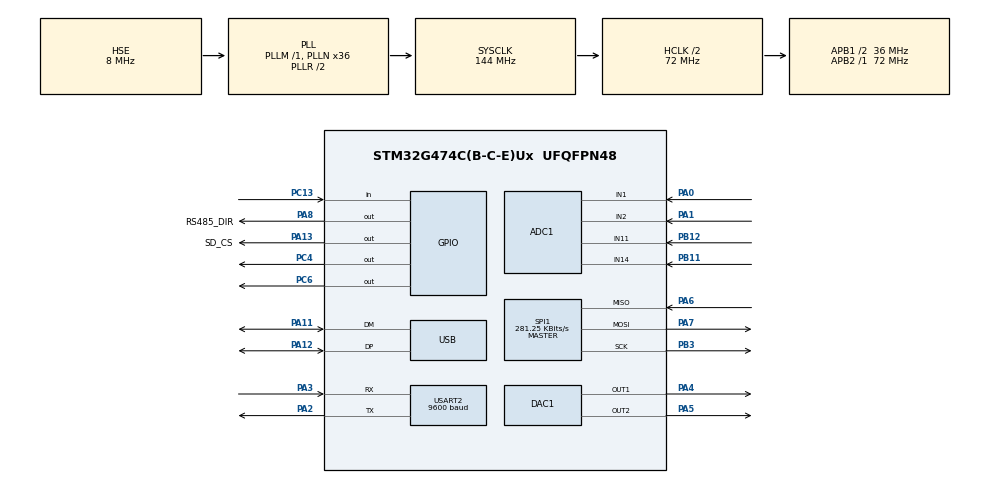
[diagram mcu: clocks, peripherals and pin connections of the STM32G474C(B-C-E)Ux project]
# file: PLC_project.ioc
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ADC1.Channel-0\#ChannelRegularConversion=ADC_CHANNEL_1
ADC1.NbrOfConversionFlag=1
ADC1.OffsetNumber-0\#ChannelRegularConversion=ADC_OFFSET_NONE
ADC1.Rank-0\#ChannelRegularConversion=1
ADC1.SamplingTime-0\#ChannelRegularConversion=ADC_SAMPLETIME_2CYCLES_5
ADC1.master=1
DAC1.DAC_Channel-DAC_OUT2_ExtAndInt=DAC_CHANNEL_2
Dma.Request0=USART2_RX
Dma.Request1=USART2_TX
Dma.USART2_RX.0.Direction=DMA_PERIPH_TO_MEMORY
Dma.USART2_RX.0.EventEnable=DISABLE
Dma.USART2_RX.0.Instance=DMA1_Channel1
Dma.USART2_RX.0.MemDataAlignment=DMA_MDATAALIGN_BYTE
Dma.USART2_RX.0.MemInc=DMA_MINC_ENABLE
Dma.USART2_RX.0.Mode=DMA_NORMAL
Dma.USART2_RX.0.PeriphDataAlignment=DMA_PDATAALIGN_BYTE
Dma.USART2_RX.0.PeriphInc=DMA_PINC_DISABLE
Dma.USART2_RX.0.Polarity=HAL_DMAMUX_REQ_GEN_RISING
Dma.USART2_RX.0.Priority=DMA_PRIORITY_HIGH
Dma.USART2_RX.0.RequestNumber=1
Dma.USART2_RX.0.SignalID=NONE
Dma.USART2_RX.0.SyncEnable=DISABLE
Dma.USART2_RX.0.SyncPolarity=HAL_DMAMUX_SYNC_NO_EVENT
Dma.USART2_RX.0.SyncRequestNumber=1
Dma.USART2_RX.0.SyncSignalID=NONE
Dma.USART2_TX.1.Direction=DMA_MEMORY_TO_PERIPH
Dma.USART2_TX.1.EventEnable=DISABLE
Dma.USART2_TX.1.Instance=DMA1_Channel2
Dma.USART2_TX.1.MemDataAlignment=DMA_MDATAALIGN_BYTE
Dma.USART2_TX.1.MemInc=DMA_MINC_ENABLE
Dma.USART2_TX.1.Mode=DMA_NORMAL
Dma.USART2_TX.1.PeriphDataAlignment=DMA_PDATAALIGN_BYTE
Dma.USART2_TX.1.PeriphInc=DMA_PINC_DISABLE
Dma.USART2_TX.1.Polarity=HAL_DMAMUX_REQ_GEN_RISING
Dma.USART2_TX.1.Priority=DMA_PRIORITY_HIGH
Dma.USART2_TX.1.RequestNumber=1
Dma.USART2_TX.1.SignalID=NONE
Dma.USART2_TX.1.SyncEnable=DISABLE
Dma.USART2_TX.1.SyncPolarity=HAL_DMAMUX_SYNC_NO_EVENT
Dma.USART2_TX.1.SyncRequestNumber=1
Dma.USART2_TX.1.SyncSignalID=NONE
Mcu.Family=STM32G4
Mcu.Name=STM32G474C(B-C-E)Ux
Mcu.Package=UFQFPN48
NVIC.DMA1_Channel1_IRQn=true\:1\:0\:true\:false\:true\:false\:true\:true
NVIC.DMA1_Channel2_IRQn=true\:1\:0\:true\:false\:true\:false\:true\:true
NVIC.PriorityGroup=NVIC_PRIORITYGROUP_4
NVIC.USART2_IRQn=true\:2\:0\:true\:false\:true\:true\:true\:true
NVIC.USB_LP_IRQn=true\:0\:0\:false\:false\:true\:false\:true\:true
PA0.Mode=IN1-Single-Ended
PA0.Signal=ADC1_IN1
PA1.Mode=IN2-Single-Ended
PA1.Signal=ADC1_IN2
PA11.Mode=Device
PA11.Signal=USB_DM
PA12.Mode=Device
PA12.Signal=USB_DP
PA13.GPIO_Label=SD_CS
PA13.Signal=GPIO_Output
PA2.Mode=Asynchronous
PA2.Signal=USART2_TX
PA3.Mode=Asynchronous
PA3.Signal=USART2_RX
PA4.Signal=COMP_DAC11_group
PA5.Signal=COMP_DAC12_group
PA6.Mode=Full_Duplex_Master
PA6.Signal=SPI1_MISO
PA7.Mode=Full_Duplex_Master
PA7.Signal=SPI1_MOSI
PA8.GPIO_Label=RS485_DIR
PA8.Signal=GPIO_Output
PB11.Mode=IN14-Single-Ended
PB11.Signal=ADC1_IN14
PB12.Mode=IN11-Single-Ended
PB12.Signal=ADC1_IN11
PB3.Mode=Full_Duplex_Master
PB3.Signal=SPI1_SCK
PC13.GPIO_PuPd=GPIO_PULLDOWN
PC13.Signal=GPIO_Input
PC4.Signal=GPIO_Output
PC6.Signal=GPIO_Output
PF0-OSC_IN.Mode=HSE-External-Oscillator
PF0-OSC_IN.Signal=RCC_OSC_IN
PF1-OSC_OUT.Mode=HSE-External-Oscillator
PF1-OSC_OUT.Signal=RCC_OSC_OUT
ProjectManager.HeapSize=0x200
ProjectManager.StackSize=0x400
ProjectManager.TargetToolchain=STM32CubeIDE
RCC.ADC12Freq_Value=144000000
RCC.ADC345Freq_Value=144000000
RCC.AHBCLKDivider=RCC_SYSCLK_DIV2
RCC.AHBFreq_Value=72000000
RCC.APB1CLKDivider=RCC_HCLK_DIV2
RCC.APB1Freq_Value=36000000
RCC.APB1TimFreq_Value=72000000
RCC.APB2Freq_Value=72000000
RCC.APB2TimFreq_Value=72000000
RCC.CortexFreq_Value=72000000
RCC.EXTERNAL_CLOCK_VALUE=12288000
RCC.HCLKFreq_Value=72000000
RCC.HSE_VALUE=8000000
RCC.HSI48_VALUE=48000000
RCC.HSI_VALUE=16000000
RCC.LSE_VALUE=32768
RCC.PLLN=36
RCC.PLLQ=RCC_PLLQ_DIV6
RCC.PLLSourceVirtual=RCC_PLLSOURCE_HSE
RCC.SYSCLKFreq_VALUE=144000000
RCC.SYSCLKSource=RCC_SYSCLKSOURCE_PLLCLK
RCC.USBFreq_Value=48000000
RCC.VCOOutputFreq_Value=288000000
SH.COMP_DAC11_group.0=DAC1_OUT1,DAC_OUT1
SH.COMP_DAC12_group.0=DAC1_OUT2,DAC_OUT2_ExtAndInt
SPI1.BaudRatePrescaler=SPI_BAUDRATEPRESCALER_256
SPI1.CalculateBaudRate=281.25 KBits/s
SPI1.DataSize=SPI_DATASIZE_8BIT
SPI1.Direction=SPI_DIRECTION_2LINES
SPI1.Mode=SPI_MODE_MASTER
SPI1.VirtualType=VM_MASTER
USART2.BaudRate=9600
USART2.StopBits=STOPBITS_2
USART2.VirtualMode-Asynchronous=VM_ASYNC
USB_DEVICE.CLASS_NAME_FS=CDC
USB_DEVICE.VirtualMode=Cdc
USB_DEVICE.VirtualModeFS=Cdc_FS
VP_FATFS_VS_Generic.Mode=User_defined
VP_SYS_VS_DBSignals.Mode=DisableDeadBatterySignals
VP_USB_DEVICE_VS_USB_DEVICE_CDC_FS.Mode=CDC_FS
board=custom

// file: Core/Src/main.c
/* USER CODE BEGIN Header */
/* USER CODE END Header */
#include "main.h"
#include "app_fatfs.h"
#include "usb_device.h"

/* USER CODE BEGIN Includes */
#include "usb_serial.h"
#include "rs485/rs485.h"
#include <string.h>
#include "io/io_digital.h"
#include "modbus/modbus.h"
/* USER CODE END Includes */

ADC_HandleTypeDef hadc1;

DAC_HandleTypeDef hdac1;

SPI_HandleTypeDef hspi1;

UART_HandleTypeDef huart2;
DMA_HandleTypeDef hdma_usart2_rx;
DMA_HandleTypeDef hdma_usart2_tx;

void SystemClock_Config(void);
static void MX_GPIO_Init(void);
static void MX_DMA_Init(void);
static void MX_USART2_UART_Init(void);
static void MX_SPI1_Init(void);
static void MX_DAC1_Init(void);
static void MX_ADC1_Init(void);

int main(void)
{

  /* MCU Configuration--------------------------------------------------------*/

  /* Reset of all peripherals, Initializes the Flash interface and the Systick. */
  HAL_Init();

  /* USER CODE BEGIN Init */
  //io_digital_add_channel(GPIOC, GPIO_PIN_6, IO_DIGITAL_OUTPUT);

  // Add Channels
  // COILS: Digital R/W: for this controller, all digital outputs
  // DISCRETE INPUTS: Digital R: for this controller, all digital inputs
  // HOLDING REGISTERS: Analogue R/W: for this controller, all analogue outputs
  // INPUT REGISTERS: Analogue R: for this controller, all analogue inputs
  io_coil_add_channel(GPIOC, GPIO_PIN_6);
  io_discrete_in_add_channel(GPIOC, GPIO_PIN_13);
  io_holding_reg_add_channel(&hdac1, DAC_CHANNEL_1);
  io_input_reg_add_channel(&hadc1, ADC_CHANNEL_1);

  /* USER CODE END Init */

  /* Configure the system clock */
  SystemClock_Config();

  /* Initialize all configured peripherals */
  MX_GPIO_Init();
  MX_DMA_Init();
  MX_USB_Device_Init();
  MX_USART2_UART_Init();
  MX_SPI1_Init();
  if (MX_FATFS_Init() != APP_OK) {
    Error_Handler();
  }
  MX_DAC1_Init();
  MX_ADC1_Init();
  /* USER CODE BEGIN 2 */
	RS485_Setup(GPIOA, RS485_DIR_Pin); // changed from PA4 to PA8 to not interfere with DAC1
	io_digital_write(0, GPIO_PIN_RESET);
	HAL_Delay(5000);

	/* SD
	// Setup FATFS
	FATFS FatFs; // Fatfs handle
	FIL fil; // File handle
	FRESULT fres; // Result after operations

	// Open the file system
	fres = f_mount(&FatFs, "", 1); // 1 = mount now
	if (fres != FR_OK) {
	  usb_serial_println("f_mount error");
	  while(1);
	}

	//Now let's try and write a file "write.txt"
	fres = f_open(&fil, "write.txt", FA_WRITE | FA_OPEN_ALWAYS | FA_CREATE_ALWAYS);

	//Copy in a string
	BYTE readBuf[30];
	strncpy((char*)readBuf, "a new file is made!", 19);
	UINT bytesWrote;
	fres = f_write(&fil, readBuf, 19, &bytesWrote);

	f_close(&fil); // close the file
	f_mount(NULL, "", 0); // un-mount the drive
	*/

	uint8_t modbus_frame[] = {0x01, 0x03, 0x00, 0x10, 0x00, 0x02, 0xC4, 0x0B};
	uint16_t frame_len = sizeof(modbus_frame) / sizeof(modbus_frame[0]);

  /* USER CODE END 2 */

  /* Infinite loop */
  /* USER CODE BEGIN WHILE */

	while(1) {
		//uint8_t msg[] = "Hello from STM32!\r\n";
		//RS485_Transmit(msg, sizeof(msg) - 1);

		// Simualate receiving modbus frame
		//modbus_handle_frame(modbus_frame, frame_len);

		// Flash on-board LED to signify non-stuck while loop (was crashing in previous tests trying to implement DMA RS485)
		//io_digital_write(0, GPIO_PIN_SET);
		//HAL_Delay(1000);
		//io_digital_write(0, GPIO_PIN_RESET);
		//HAL_Delay(1000);
	}
    /* USER CODE END WHILE */

}

void SystemClock_Config(void)
{
  RCC_OscInitTypeDef RCC_OscInitStruct = {0};
  RCC_ClkInitTypeDef RCC_ClkInitStruct = {0};

  /** Configure the main internal regulator output voltage
  */
  HAL_PWREx_ControlVoltageScaling(PWR_REGULATOR_VOLTAGE_SCALE1);

  /** Initializes the RCC Oscillators according to the specified parameters
  * in the RCC_OscInitTypeDef structure.
  */
  RCC_OscInitStruct.OscillatorType = RCC_OSCILLATORTYPE_HSE;
  RCC_OscInitStruct.HSEState = RCC_HSE_ON;
  RCC_OscInitStruct.PLL.PLLState = RCC_PLL_ON;
  RCC_OscInitStruct.PLL.PLLSource = RCC_PLLSOURCE_HSE;
  RCC_OscInitStruct.PLL.PLLM = RCC_PLLM_DIV1;
  RCC_OscInitStruct.PLL.PLLN = 36;
  RCC_OscInitStruct.PLL.PLLP = RCC_PLLP_DIV2;
  RCC_OscInitStruct.PLL.PLLQ = RCC_PLLQ_DIV6;
  RCC_OscInitStruct.PLL.PLLR = RCC_PLLR_DIV2;
  if (HAL_RCC_OscConfig(&RCC_OscInitStruct) != HAL_OK)
  {
    Error_Handler();
  }

  /** Initializes the CPU, AHB and APB buses clocks
  */
  RCC_ClkInitStruct.ClockType = RCC_CLOCKTYPE_HCLK|RCC_CLOCKTYPE_SYSCLK
                              |RCC_CLOCKTYPE_PCLK1|RCC_CLOCKTYPE_PCLK2;
  RCC_ClkInitStruct.SYSCLKSource = RCC_SYSCLKSOURCE_PLLCLK;
  RCC_ClkInitStruct.AHBCLKDivider = RCC_SYSCLK_DIV2;
  RCC_ClkInitStruct.APB1CLKDivider = RCC_HCLK_DIV2;
  RCC_ClkInitStruct.APB2CLKDivider = RCC_HCLK_DIV1;

  if (HAL_RCC_ClockConfig(&RCC_ClkInitStruct, FLASH_LATENCY_2) != HAL_OK)
  {
    Error_Handler();
  }
}

static void MX_ADC1_Init(void)
{

  ADC_MultiModeTypeDef multimode = {0};
  ADC_ChannelConfTypeDef sConfig = {0};

  /** Common config
  */
  hadc1.Instance = ADC1;
  hadc1.Init.ClockPrescaler = ADC_CLOCK_SYNC_PCLK_DIV2;
  hadc1.Init.Resolution = ADC_RESOLUTION_12B;
  hadc1.Init.DataAlign = ADC_DATAALIGN_RIGHT;
  hadc1.Init.GainCompensation = 0;
  hadc1.Init.ScanConvMode = ADC_SCAN_DISABLE;
  hadc1.Init.EOCSelection = ADC_EOC_SINGLE_CONV;
  hadc1.Init.LowPowerAutoWait = DISABLE;
  hadc1.Init.ContinuousConvMode = DISABLE;
  hadc1.Init.NbrOfConversion = 1;
  hadc1.Init.DiscontinuousConvMode = DISABLE;
  hadc1.Init.ExternalTrigConv = ADC_SOFTWARE_START;
  hadc1.Init.ExternalTrigConvEdge = ADC_EXTERNALTRIGCONVEDGE_NONE;
  hadc1.Init.DMAContinuousRequests = DISABLE;
  hadc1.Init.Overrun = ADC_OVR_DATA_PRESERVED;
  hadc1.Init.OversamplingMode = DISABLE;
  if (HAL_ADC_Init(&hadc1) != HAL_OK)
  {
    Error_Handler();
  }

  /** Configure the ADC multi-mode
  */
  multimode.Mode = ADC_MODE_INDEPENDENT;
  if (HAL_ADCEx_MultiModeConfigChannel(&hadc1, &multimode) != HAL_OK)
  {
    Error_Handler();
  }

  /** Configure Regular Channel
  */
  sConfig.Channel = ADC_CHANNEL_1;
  sConfig.Rank = ADC_REGULAR_RANK_1;
  sConfig.SamplingTime = ADC_SAMPLETIME_2CYCLES_5;
  sConfig.SingleDiff = ADC_SINGLE_ENDED;
  sConfig.OffsetNumber = ADC_OFFSET_NONE;
  sConfig.Offset = 0;
  if (HAL_ADC_ConfigChannel(&hadc1, &sConfig) != HAL_OK)
  {
    Error_Handler();
  }

}

static void MX_DAC1_Init(void)
{

  DAC_ChannelConfTypeDef sConfig = {0};

  /** DAC Initialization
  */
  hdac1.Instance = DAC1;
  if (HAL_DAC_Init(&hdac1) != HAL_OK)
  {
    Error_Handler();
  }

  /** DAC channel OUT1 config
  */
  sConfig.DAC_HighFrequency = DAC_HIGH_FREQUENCY_INTERFACE_MODE_AUTOMATIC;
  sConfig.DAC_DMADoubleDataMode = DISABLE;
  sConfig.DAC_SignedFormat = DISABLE;
  sConfig.DAC_SampleAndHold = DAC_SAMPLEANDHOLD_DISABLE;
  sConfig.DAC_Trigger = DAC_TRIGGER_NONE;
  sConfig.DAC_Trigger2 = DAC_TRIGGER_NONE;
  sConfig.DAC_OutputBuffer = DAC_OUTPUTBUFFER_ENABLE;
  sConfig.DAC_ConnectOnChipPeripheral = DAC_CHIPCONNECT_EXTERNAL;
  sConfig.DAC_UserTrimming = DAC_TRIMMING_FACTORY;
  if (HAL_DAC_ConfigChannel(&hdac1, &sConfig, DAC_CHANNEL_1) != HAL_OK)
  {
    Error_Handler();
  }

  /** DAC channel OUT2 config
  */
  sConfig.DAC_ConnectOnChipPeripheral = DAC_CHIPCONNECT_BOTH;
  if (HAL_DAC_ConfigChannel(&hdac1, &sConfig, DAC_CHANNEL_2) != HAL_OK)
  {
    Error_Handler();
  }

}

static void MX_SPI1_Init(void)
{

  /* SPI1 parameter configuration*/
  hspi1.Instance = SPI1;
  hspi1.Init.Mode = SPI_MODE_MASTER;
  hspi1.Init.Direction = SPI_DIRECTION_2LINES;
  hspi1.Init.DataSize = SPI_DATASIZE_8BIT;
  hspi1.Init.CLKPolarity = SPI_POLARITY_LOW;
  hspi1.Init.CLKPhase = SPI_PHASE_1EDGE;
  hspi1.Init.NSS = SPI_NSS_SOFT;
  hspi1.Init.BaudRatePrescaler = SPI_BAUDRATEPRESCALER_256;
  hspi1.Init.FirstBit = SPI_FIRSTBIT_MSB;
  hspi1.Init.TIMode = SPI_TIMODE_DISABLE;
  hspi1.Init.CRCCalculation = SPI_CRCCALCULATION_DISABLE;
  hspi1.Init.CRCPolynomial = 7;
  hspi1.Init.CRCLength = SPI_CRC_LENGTH_DATASIZE;
  hspi1.Init.NSSPMode = SPI_NSS_PULSE_ENABLE;
  if (HAL_SPI_Init(&hspi1) != HAL_OK)
  {
    Error_Handler();
  }

}

static void MX_USART2_UART_Init(void)
{

  huart2.Instance = USART2;
  huart2.Init.BaudRate = 9600;
  huart2.Init.WordLength = UART_WORDLENGTH_8B;
  huart2.Init.StopBits = UART_STOPBITS_2;
  huart2.Init.Parity = UART_PARITY_NONE;
  huart2.Init.Mode = UART_MODE_TX_RX;
  huart2.Init.HwFlowCtl = UART_HWCONTROL_NONE;
  huart2.Init.OverSampling = UART_OVERSAMPLING_16;
  huart2.Init.OneBitSampling = UART_ONE_BIT_SAMPLE_DISABLE;
  huart2.Init.ClockPrescaler = UART_PRESCALER_DIV1;
  huart2.AdvancedInit.AdvFeatureInit = UART_ADVFEATURE_NO_INIT;
  if (HAL_UART_Init(&huart2) != HAL_OK)
  {
    Error_Handler();
  }
  if (HAL_UARTEx_SetTxFifoThreshold(&huart2, UART_TXFIFO_THRESHOLD_1_8) != HAL_OK)
  {
    Error_Handler();
  }
  if (HAL_UARTEx_SetRxFifoThreshold(&huart2, UART_RXFIFO_THRESHOLD_1_8) != HAL_OK)
  {
    Error_Handler();
  }
  if (HAL_UARTEx_DisableFifoMode(&huart2) != HAL_OK)
  {
    Error_Handler();
  }

}

static void MX_DMA_Init(void)
{

  /* DMA controller clock enable */
  __HAL_RCC_DMAMUX1_CLK_ENABLE();
  __HAL_RCC_DMA1_CLK_ENABLE();

  /* DMA interrupt init */
  /* DMA1_Channel1_IRQn interrupt configuration */
  HAL_NVIC_SetPriority(DMA1_Channel1_IRQn, 1, 0);
  HAL_NVIC_EnableIRQ(DMA1_Channel1_IRQn);
  /* DMA1_Channel2_IRQn interrupt configuration */
  HAL_NVIC_SetPriority(DMA1_Channel2_IRQn, 1, 0);
  HAL_NVIC_EnableIRQ(DMA1_Channel2_IRQn);

}

static void MX_GPIO_Init(void)
{
  GPIO_InitTypeDef GPIO_InitStruct = {0};

  /* GPIO Ports Clock Enable */
  __HAL_RCC_GPIOC_CLK_ENABLE();
  __HAL_RCC_GPIOF_CLK_ENABLE();
  __HAL_RCC_GPIOA_CLK_ENABLE();
  __HAL_RCC_GPIOB_CLK_ENABLE();

  /*Configure GPIO pin Output Level */
  HAL_GPIO_WritePin(GPIOC, GPIO_PIN_4|GPIO_PIN_6, GPIO_PIN_RESET);

  /*Configure GPIO pin Output Level */
  HAL_GPIO_WritePin(GPIOA, RS485_DIR_Pin|SD_CS_Pin, GPIO_PIN_RESET);

  /*Configure GPIO pin : PC13 */
  GPIO_InitStruct.Pin = GPIO_PIN_13;
  GPIO_InitStruct.Mode = GPIO_MODE_INPUT;
  GPIO_InitStruct.Pull = GPIO_PULLDOWN;
  HAL_GPIO_Init(GPIOC, &GPIO_InitStruct);

  /*Configure GPIO pins : PC4 PC6 */
  GPIO_InitStruct.Pin = GPIO_PIN_4|GPIO_PIN_6;
  GPIO_InitStruct.Mode = GPIO_MODE_OUTPUT_PP;
  GPIO_InitStruct.Pull = GPIO_NOPULL;
  GPIO_InitStruct.Speed = GPIO_SPEED_FREQ_LOW;
  HAL_GPIO_Init(GPIOC, &GPIO_InitStruct);

  /*Configure GPIO pins : RS485_DIR_Pin SD_CS_Pin */
  GPIO_InitStruct.Pin = RS485_DIR_Pin|SD_CS_Pin;
  GPIO_InitStruct.Mode = GPIO_MODE_OUTPUT_PP;
  GPIO_InitStruct.Pull = GPIO_NOPULL;
  GPIO_InitStruct.Speed = GPIO_SPEED_FREQ_LOW;
  HAL_GPIO_Init(GPIOA, &GPIO_InitStruct);

}

void Error_Handler(void)
{
}
